# psc3_p8_ppca register map
Vendor: Infineon Technologies; Series: PSC3_P8; File version: 1.0
CPU: CM33 r0p1, little endian, MPU, FPU, DSP, VTOR, 3 interrupt priority bits, 143 interrupts
Registers are 32-bit, read-write, reset 0x0 unless marked. A register's access mark holds for its fields unless they carry their own. Offsets are from the block's base; [hi:lo] are bit positions; 'fields as' and 'values as' point back to an identical list.

## EFUSE — EFUSE MXS40 registers
Base 0x68610000
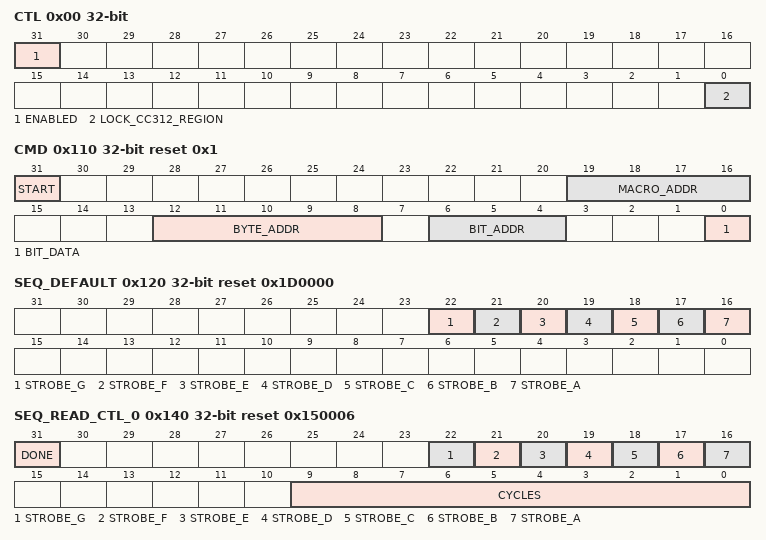
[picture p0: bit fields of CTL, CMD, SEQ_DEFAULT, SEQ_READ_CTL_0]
0x00 CTL — Control
  [31] ENABLED — IP enable: '0': Disabled. All non-retention registers (command and status registers) are reset to their default value when the IP is disabled. All retention registers retain their value when the IP is disabled. '1': Enabled.
  [0] LOCK_CC312_REGION write-1-sets — CC312 lock - when set locks 8 bytes beyond the end of the PROT_MASTER defined space for read access.
0x110 CMD reset 0x1 — Command
  [31] START write-1-sets — FW sets this field to '1' to start a program operation. HW sets this field to '0' to indicate that the operation has completed. Note: it is good practice to verify the result of a program operation by reading back a programmed eFUSE memory location. Programming can only change an eFUSE memory bit from '0' to '1'; i.e. a programming operation is a 'one-off' operation for each eFUSE memory bit: once a bit is changed to '1', it can NEVER be changed back to '0' as a hardware fuse is blown. Programming a memory bit to '1' requires blowing a fuse and requires an eFUSE macro operation. Therefore, this programmiong operation takes time (as specified by the SEQ_PROGRAM_CTL reguisters). Programming amemory bit to '0' does not require an eFUSE macro operation (it is the default eFUSE macro state). Therefore, this programming operation is almost instantaneous. Note: during a program operation, a read operation can not be performed. An AHB-Lite read transfer to the eFUSE memory during a program operation results in an AHB-Lite bus error.
  [19:16] MACRO_ADDR — Macro address. This field specifies an eFUSE macro.
  [12:8] BYTE_ADDR — Byte address. This field specifies a Byte within a eFUSE macro (each macro has 32 B).
  [6:4] BIT_ADDR — Bit address. This field specifies a bit within a Byte.
  [0] BIT_DATA — Bit data. This field specifies the bit value that is to be programmed into the eFUSE macro array. The address of the bit is specified by the BIT_ADDR, BYTE_ADDR, and MACRO_ADDR fields.
0x120 SEQ_DEFAULT reset 0x1D0000 — Sequencer Default value
  [22] STROBE_G — Specifies value of eFUSE control signal strobe_g
  [21] STROBE_F — Specifies value of eFUSE control signal strobe_f
  [20] STROBE_E — Specifies value of eFUSE control signal strobe_e
  [19] STROBE_D — Specifies value of eFUSE control signal strobe_d
  [18] STROBE_C — Specifies value of eFUSE control signal strobe_c
  [17] STROBE_B — Specifies value of eFUSEcontrol signal strobe_b
  [16] STROBE_A — Specifies value of eFUSE control signal strobe_f
0x140 SEQ_READ_CTL_0 reset 0x150006 — Sequencer read control 0
  [31] DONE — When set to 1 indicates that the Read cycle ends when the current cycle count reaches 0.
  [22] STROBE_G — Specifies value of eFUSE control signal strobe_g
  [21] STROBE_F — Specifies value of eFUSE control signal strobe_f
  [20] STROBE_E — Specifies value of eFUSE control signal strobe_e
  [19] STROBE_D — Specifies value of eFUSE control signal strobe_d
  [18] STROBE_C — Specifies value of eFUSE control signal strobe_c
  [17] STROBE_B — Specifies value of eFUSEcontrol signal strobe_b
  [16] STROBE_A — Specifies value of eFUSE control signal strobe_f
  [9:0] CYCLES — Number of IP clock cycles (minus 1). This field is in the range of [0, 1023], allowing for a time of [1, 1024] IP clock cycles.
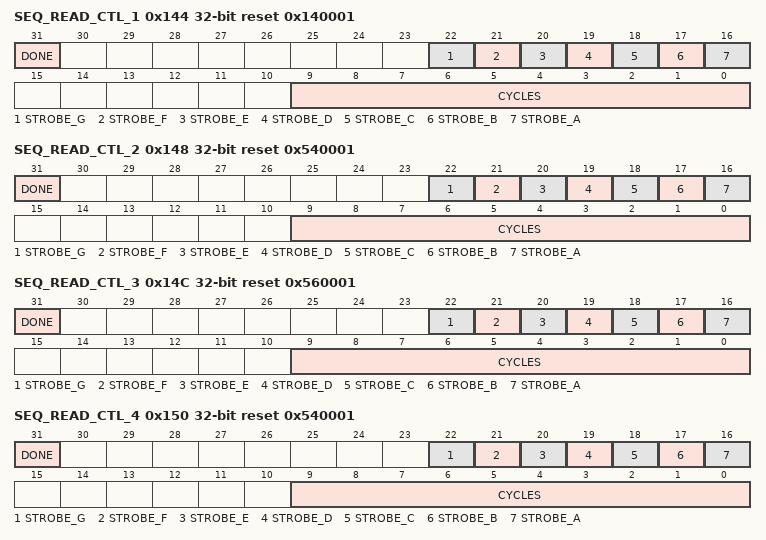
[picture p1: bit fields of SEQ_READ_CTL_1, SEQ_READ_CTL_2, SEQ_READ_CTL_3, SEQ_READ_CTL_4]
0x144 SEQ_READ_CTL_1 reset 0x140001 — Sequencer read control 1
  fields as SEQ_READ_CTL_0
0x148 SEQ_READ_CTL_2 reset 0x540001 — Sequencer read control 2
  fields as SEQ_READ_CTL_0
0x14C SEQ_READ_CTL_3 reset 0x560001 — Sequencer read control 3
  fields as SEQ_READ_CTL_0
0x150 SEQ_READ_CTL_4 reset 0x540001 — Sequencer read control 4
  fields as SEQ_READ_CTL_0
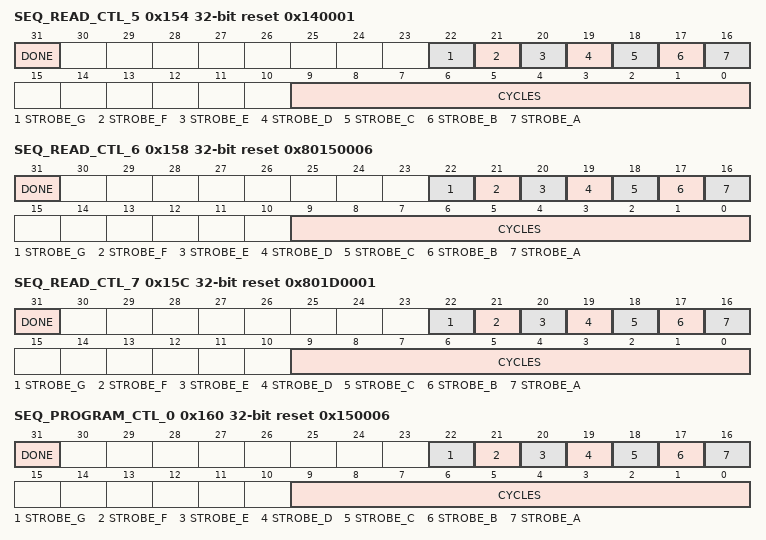
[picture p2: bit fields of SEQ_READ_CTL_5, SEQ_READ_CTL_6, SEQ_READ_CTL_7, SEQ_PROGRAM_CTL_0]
0x154 SEQ_READ_CTL_5 reset 0x140001 — Sequencer read control 5
  fields as SEQ_READ_CTL_0
0x158 SEQ_READ_CTL_6 reset 0x80150006 — Sequencer read control 6
  fields as SEQ_READ_CTL_0
0x15C SEQ_READ_CTL_7 reset 0x801D0001 — Sequencer read control 7
  fields as SEQ_READ_CTL_0
0x160 SEQ_PROGRAM_CTL_0 reset 0x150006 — Sequencer program control 0
  [31] DONE — When set to 1 indicates that the Program cycle ends when the current cycle count reaches 0.
  [22] STROBE_G — Specifies value of eFUSE control signal strobe_g
  [21] STROBE_F — Specifies value of eFUSE control signal strobe_f
  [20] STROBE_E — Specifies value of eFUSE control signal strobe_e
  [19] STROBE_D — Specifies value of eFUSE control signal strobe_d
  [18] STROBE_C — Specifies value of eFUSE control signal strobe_c
  [17] STROBE_B — Specifies value of eFUSEcontrol signal strobe_b
  [16] STROBE_A — Specifies value of eFUSE control signal strobe_a
  [9:0] CYCLES — Number of IP clock cycles (minus 1). This field is in the range of [0, 1023], allowing for a time of [1, 1024] IP clock cycles.
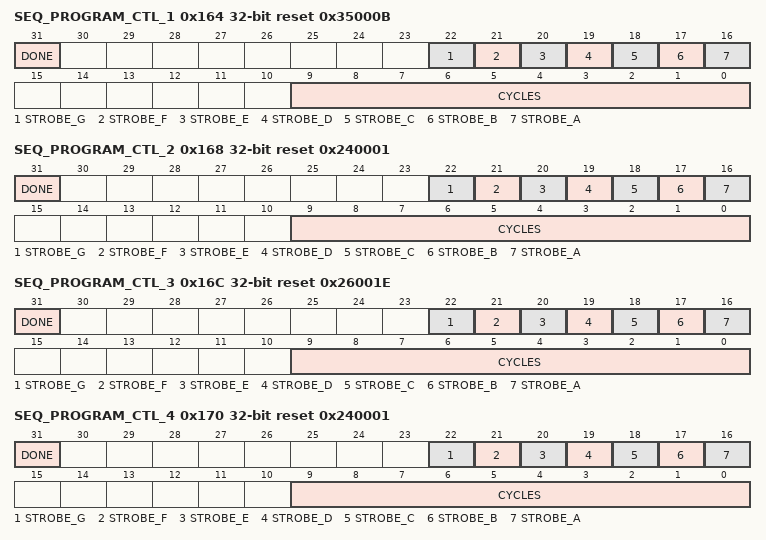
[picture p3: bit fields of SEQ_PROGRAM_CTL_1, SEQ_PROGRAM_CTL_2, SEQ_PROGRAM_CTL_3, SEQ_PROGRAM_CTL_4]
0x164 SEQ_PROGRAM_CTL_1 reset 0x35000B — Sequencer program control 1
  fields as SEQ_PROGRAM_CTL_0
0x168 SEQ_PROGRAM_CTL_2 reset 0x240001 — Sequencer program control 2
  fields as SEQ_PROGRAM_CTL_0
0x16C SEQ_PROGRAM_CTL_3 reset 0x26001E — Sequencer program control 3
  fields as SEQ_PROGRAM_CTL_0
0x170 SEQ_PROGRAM_CTL_4 reset 0x240001 — Sequencer program control 4
  fields as SEQ_PROGRAM_CTL_0
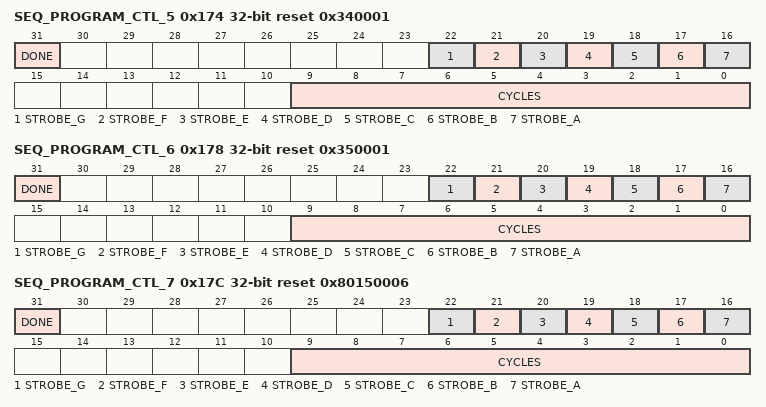
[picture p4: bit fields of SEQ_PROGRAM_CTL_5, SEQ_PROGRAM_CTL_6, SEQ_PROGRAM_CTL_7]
0x174 SEQ_PROGRAM_CTL_5 reset 0x340001 — Sequencer program control 5
  fields as SEQ_PROGRAM_CTL_0
0x178 SEQ_PROGRAM_CTL_6 reset 0x350001 — Sequencer program control 6
  fields as SEQ_PROGRAM_CTL_0
0x17C SEQ_PROGRAM_CTL_7 reset 0x80150006 — Sequencer program control 7
  fields as SEQ_PROGRAM_CTL_0
0x180 BOOTROW ro reset not defined — Content of Boot Row latches at power-on-reset
  [31:0] BOOT_ROW_DATA — Contains the Boot Row data held by the Boot Row latches.
